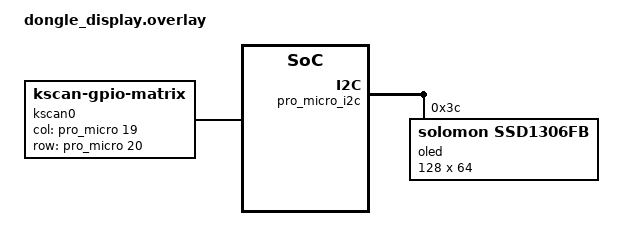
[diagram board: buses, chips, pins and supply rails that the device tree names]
/*
 * Copyright (c) 2024 The ZMK Contributors
 * SPDX-License-Identifier: MIT
 */

#include <dt-bindings/zmk/matrix_transform.h>

/ {
    chosen {
        zmk,kscan = &kscan0;
        zmk,matrix-transform = &default_transform;
    };

    kscan0: kscan {
        compatible = "zmk,kscan-gpio-matrix";
        wakeup-source;
        diode-direction = "col2row";
        col-gpios = <&pro_micro 19 GPIO_ACTIVE_HIGH>;
        row-gpios = <&pro_micro 20 (GPIO_ACTIVE_HIGH | GPIO_PULL_DOWN)>;
    };

    default_transform: keymap_transform_0 {
        compatible = "zmk,matrix-transform";
        columns = <1>;
        rows = <1>;
        map = <RC(0,0)>;
    };
};

&pro_micro_i2c {
    status = "okay";
    
    oled: ssd1306@3c {
        compatible = "solomon,ssd1306fb";
        reg = <0x3c>;
        width = <128>;
        height = <64>;
        segment-offset = <0>;
        page-offset = <0>;
        display-offset = <0>;
        multiplex-ratio = <63>;
        segment-remap;
        com-invdir;
        prechargep = <0x22>;
    };
};

/ {
    chosen {
        zephyr,display = &oled;
    };
};
